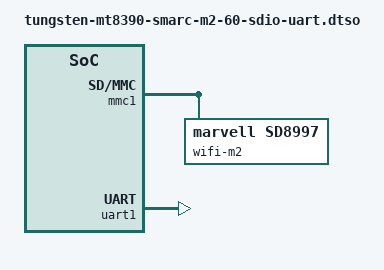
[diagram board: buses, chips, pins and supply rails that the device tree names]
// SPDX-License-Identifier: (GPL-2.0+ OR MIT)
/*
 * SDIO 60 SDIO-UART module
 *
 * Copyright (C) 2026 Ezurio LLC
 */

/dts-v1/;
/plugin/;

// M.2 SDIO is disabled by default on SMARC carrier board
// requires switching 0 Ohm resistors to enable	

&reg_mmc1_en {
	vin-supply = <&reg_slow_clock_carrier>;

	startup-delay-us = <1000>;
	off-on-delay-us = <100000>;
};

&mmc1 {
	wifi-m2 {
		compatible = "marvell,sd8997";
		fwtype = "sdio-uart";
	};
};

&uart1 {
	status = "okay";
};
